# NUC100CN_v1 register map
File version: 1.0
Registers are 32-bit, read-write, reset 0x0 unless marked. A register's access mark holds for its fields unless they carry their own. Offsets are from the block's base; [hi:lo] are bit positions.

## EBI — EBI Register Map
Base 0x50010000
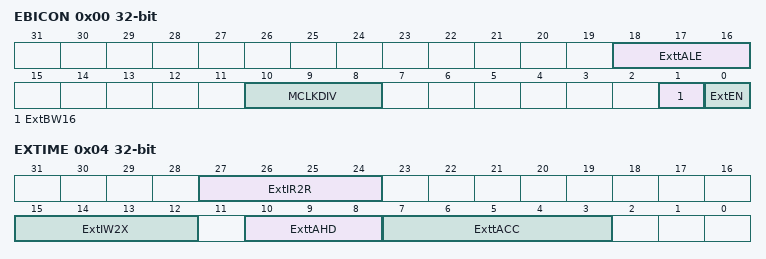
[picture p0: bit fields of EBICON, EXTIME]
0x00 EBICON — External Bus Interface General Control Register
  [18:16] ExttALE — Expand Time of ALE. The ALE width (tALE) to latch the address can be controlled by ExttALE.
  [10:8] MCLKDIV — External Output Clock Divider
  [1] ExtBW16 — EBI data width 16-bit. This bit defines if the data bus is 8-bit or 16-bit.
    0=EBI data width is 8-bit; 1=EBI data width is 16-bit
  [0] ExtEN — EBI Enable. This bit is the functional enable bit for EBI.
    0=EBI function Disabled; 1=EBI function Enabled
0x04 EXTIME — External Bus Interface Timing Control Register
  [27:24] ExtIR2R — Idle State Cycle Between Read-Read. When read action is finish and next action is going to read, idle state is inserted and nCS return to high if ExtIR2R is not zero.
  [15:12] ExtIW2X — Idle State Cycle After Write. When write action is finished, idle state is inserted and nCS return to high if ExtIW2X is not zero.
  [10:8] ExttAHD — EBI Data Access Hold Time. ExttAHD define data access hold time (tAHD).
  [7:3] ExttACC — EBI Data Access Time. ExttACC define data access time (tACC).

## FMC — FMC Register Map
Base 0x5000C000
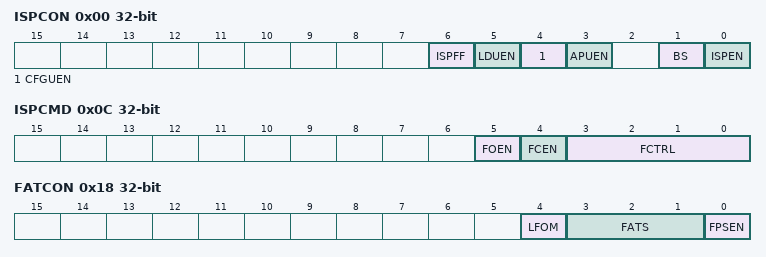
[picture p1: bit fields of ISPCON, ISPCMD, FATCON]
0x00 ISPCON — ISP Control Register
  [6] ISPFF — ISP Fail Flag (Write-protection Bit). This bit is set by hardware when a triggered ISP meets any of the following conditions: (1) APROM writes to itself if APUEN is set to 0 (2) LDROM writes to itself (3) CONFIG is erased/programmed if CFGUEN is set to 0 (4) Destination address is illegal, such as over an available range. Write 1 to clear.
  [5] LDUEN — LDROM Update Enable (Write-protection Bit). LDROM update enable bit.
    0=LDROM cannot be updated; 1=LDROM can be updated when the chip runs in APROM
  [4] CFGUEN — Enable Config-bits Update by ISP (Write-protection Bit)
    0=Disabled ISP to update config-bits; 1=Enabled ISP to update config-bits
  [3] APUEN — APROM Update Enable (Write-protection Bit)
    0=APROM cannot be updated when the chip runs in APROM; 1=APROM can be updated when the chip runs in APROM
  [1] BS — Boot Select (Write-protection Bit). Set/clear this bit to select next booting from LDROM/APROM, respectively. This bit also functions as chip booting status flag, which can be used to check where chip booted from. This bit is initiated with the inversed value of CBS in Config0 after any reset is happened except CPU reset (RSTS_CPU is 1) or system reset (RSTS_SYS) is happened
    0=Boot from APROM; 1=Boot from LDROM
  [0] ISPEN — ISP Enable (Write-protection Bit). ISP function enable bit. Set this bit to enable ISP function.
    0=ISP function Disabled; 1=ISP function Enabled
0x04 ISPADR — ISP Address Register
  [31:0] ISPADR — ISP Address. The NuMicro( NUC100 Series has a maximum 32Kx32 embedded flash, which supports word program only. ISPADR[1:0] must be kept 00b for ISP operation.
0x08 ISPDAT — ISP Data Register
  [31:0] ISPDAT — ISP Data. Write data to this register before ISP program operation. Read data from this register after ISP read operation
0x0C ISPCMD — ISP Command Register
  [5] FOEN — ISP Command
  [4] FCEN — ISP Command
  [3:0] FCTRL — ISP Command
0x10 ISPTRG — ISP Trigger Control Register
  [0] ISPGO — ISP start trigger (Write-protection Bit). Write 1 to start ISP operation and this bit will be cleared to 0 by hardware automatically when ISP operation is finished. This bit is the protected bit, It means programming this bit needs to write "59h", "16h", "88h" to address 0x5000_0100 to disable register protection. Refer to the register REGWRPROT at address GCR_BA+0x100
    0=ISP operation is finished; 1=ISP is on going
0x14 DFBADR ro reset 0x1F000 — Data Flash Start Address (APROM Size Is Less Than 128KB) (*1)
  [31:0] DFBADR — Data Flash Base Address. This register indicates data flash start address. It is a read only register. For 128KB flash memory device, the data flash size is defined by user configuration, register content is loaded from Config1 when chip power on but for 64/32KB device, it is fixed at 0x0001_F000.
0x18 FATCON — Flash Access Time Control Register
  [4] LFOM — Low Frequency Optimization Mode (Write-protection Bit). When chip operation frequency is lower than 25 MHz, chip can work more efficiently by setting this bit to 1
    0=Low Frequency Optimization mode Disabled; 1=Low Frequency Optimization mode Enabled
  [3:1] FATS — Flash Access Time Window Selection (Write-protection Bits)
  [0] FPSEN — Flash Power Save Enable (Write-protection Bit). If CPU clock is slower than 24 MHz, then s/w can enable flash power saving function.
    0=Flash power saving Disabled; 1=Flash power saving Enabled
